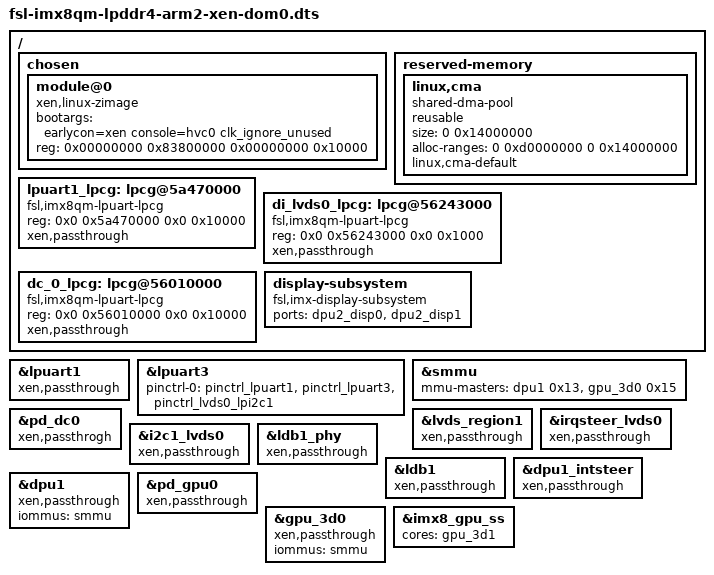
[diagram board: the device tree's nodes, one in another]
/*
 * Copyright 2017 NXP
 *
 * This program is free software; you can redistribute it and/or
 * modify it under the terms of the GNU General Public License
 * as published by the Free Software Foundation; either version 2
 * of the License, or (at your option) any later version.
 *
 * This program is distributed in the hope that it will be useful,
 * but WITHOUT ANY WARRANTY; without even the implied warranty of
 * MERCHANTABILITY or FITNESS FOR A PARTICULAR PURPOSE.  See the
 * GNU General Public License for more details.
 */

#include "fsl-imx8qm-lpddr4-arm2-it6263.dts"

/ {
	/delete-node/ rtc;

	chosen {
		#address-cells = <2>;
		#size-cells = <2>;

		/* Potentially overwritten by uboot: */
		module@0 {
			compatible = "xen,linux-zimage", "xen,multiboot-module";
			bootargs = "earlycon=xen console=hvc0 clk_ignore_unused";
			reg = <0x00000000 0x83800000 0x00000000 0x10000>;
		};
	};

	reserved-memory {
		/* global autoconfigured region for contiguous allocations */
		linux,cma {
			compatible = "shared-dma-pool";
			reusable;
			size = <0 0x14000000>;
			alloc-ranges = <0 0xd0000000 0 0x14000000>;
			linux,cma-default;
		};
	};

	lpuart1_lpcg: lpcg@5a470000 {
		compatible = "fsl,imx8qm-lpuart-lpcg";
		reg = <0x0 0x5a470000 0x0 0x10000>;
		xen,passthrough;
	};

	di_lvds0_lpcg: lpcg@56243000 {
		compatible = "fsl,imx8qm-lpuart-lpcg";
		reg = <0x0 0x56243000 0x0 0x1000>;
		xen,passthrough;
	};

	dc_0_lpcg: lpcg@56010000 {
		compatible = "fsl,imx8qm-lpuart-lpcg";
		reg = <0x0 0x56010000 0x0 0x10000>;
		xen,passthrough;
	};

	display-subsystem {
		compatible = "fsl,imx-display-subsystem";
		ports = <&dpu2_disp0>, <&dpu2_disp1>;
	};

};

&lpuart1 {
	xen,passthrough;
};

&lpuart3 {
	//#pinctrl-names = "default";
	// HACK:
	pinctrl-0 = <&pinctrl_lpuart1 &pinctrl_lpuart3 &pinctrl_lvds0_lpi2c1>;
};


/* SMMU */
&smmu {
	#iommu-cells = <0>;
	mmu-masters = <&dpu1 0x13>, <&gpu_3d0 0x15>;
};


/* DC0 */
&pd_dc0 {
	xen,passthrogh;
};

&lvds_region1 {
	xen,passthrough;
};

&irqsteer_lvds0 {
	xen,passthrough;
};

&i2c1_lvds0 {
	xen,passthrough;
};

&ldb1_phy {
	xen,passthrough;
};

&ldb1 {
	xen,passthrough;
};

&dpu1_intsteer {
	xen,passthrough;
};

&dpu1 {
	xen,passthrough;
	#stream-id-cells = <1>;
	iommus = <&smmu>;
};


/* GPU */
&pd_gpu0 {
	xen,passthrough;
};

&gpu_3d0 {
	xen,passthrough;
	#stream-id-cells = <1>;
	iommus = <&smmu>;
};

&imx8_gpu_ss {
	cores = <&gpu_3d1>;
	/delete-property/ reg;
	/delete-property/ reg-names;
};
